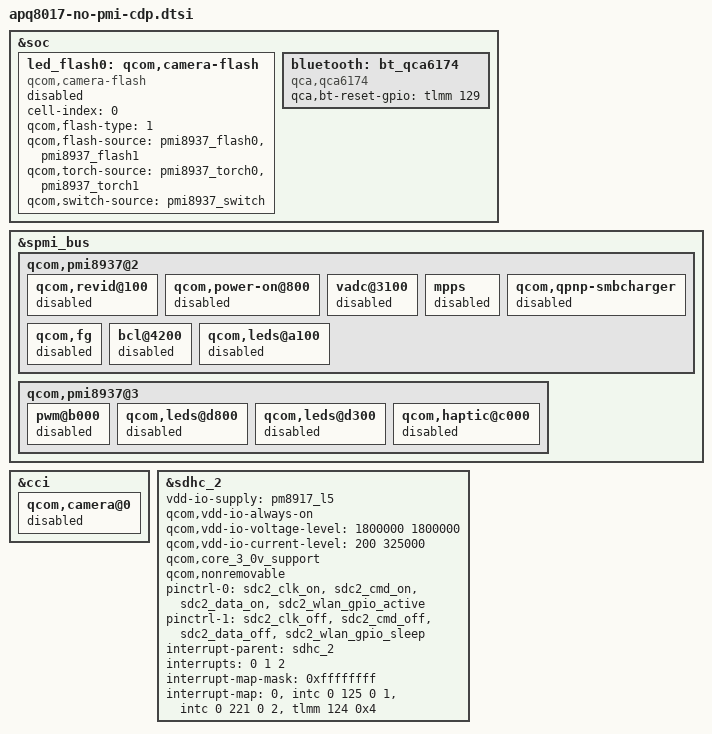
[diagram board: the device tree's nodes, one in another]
/*
 * Copyright (c) 2016, The Linux Foundation. All rights reserved.
 *
 * This program is free software; you can redistribute it and/or modify
 * it under the terms of the GNU General Public License version 2 and
 * only version 2 as published by the Free Software Foundation.
 *
 * This program is distributed in the hope that it will be useful,
 * but WITHOUT ANY WARRANTY; without even the implied warranty of
 * MERCHANTABILITY or FITNESS FOR A PARTICULAR PURPOSE.  See the
 * GNU General Public License for more details.
 */

#include "msm-pmi8937.dtsi"
#include "msm8917-cdp.dtsi"
#include "msm8917-audio-cdp.dtsi"

&soc {
	led_flash0: qcom,camera-flash {
		status = "disabled";
		cell-index = <0>;
		compatible = "qcom,camera-flash";
		qcom,flash-type = <1>;
		qcom,flash-source = <&pmi8937_flash0 &pmi8937_flash1>;
		qcom,torch-source = <&pmi8937_torch0 &pmi8937_torch1>;
		qcom,switch-source = <&pmi8937_switch>;
	};

	bluetooth: bt_qca6174 {
		compatible = "qca,qca6174";
		qca,bt-reset-gpio = <&tlmm 129 0>; /* BT_EN */
	};
};

/* delete all PMI nodes */
&spmi_bus {
	qcom,pmi8937@2 {
		qcom,revid@100 {
			status = "disabled";
		};

		qcom,power-on@800 {
			status = "disabled";
		};

		vadc@3100 {
			status = "disabled";
		};

		mpps {
			status = "disabled";
		};

		qcom,qpnp-smbcharger {
			status = "disabled";
		};

		qcom,fg {
			status = "disabled";
		};

		bcl@4200 {
			status = "disabled";
		};

		qcom,leds@a100 {
			status = "disabled";
		};
	};

	qcom,pmi8937@3 {
		pwm@b000 {
			status = "disabled";
		};

		qcom,leds@d800 {
			status = "disabled";
		};

		qcom,leds@d300 {
			status = "disabled";
		};

		qcom,haptic@c000 {
			status = "disabled";
		};
	};
};

&cci {
	qcom,camera@0 {
		status = "disabled";
	};
};

&sdhc_2 {
	/* device core power supply */
	/delete-property/vdd-supply;
	/delete-property/qcom,vdd-voltage-level;
	/delete-property/qcom,vdd-current-level;

	/* device communication power supply */
	vdd-io-supply = <&pm8917_l5>;
	qcom,vdd-io-always-on;
	qcom,vdd-io-voltage-level = <1800000 1800000>;
	qcom,vdd-io-current-level = <200 325000>;

	qcom,core_3_0v_support;
	qcom,nonremovable;

	pinctrl-names = "active", "sleep";
	pinctrl-0 = <&sdc2_clk_on &sdc2_cmd_on &sdc2_data_on
			&sdc2_wlan_gpio_active>;
	pinctrl-1 = <&sdc2_clk_off &sdc2_cmd_off &sdc2_data_off
			&sdc2_wlan_gpio_sleep>;

	#address-cells = <0>;
	interrupt-parent = <&sdhc_2>;
	interrupts = <0 1 2>;
	#interrupt-cells = <1>;
	interrupt-map-mask = <0xffffffff>;
	interrupt-map = <0 &intc 0 125 0
		1 &intc 0 221 0
		2 &tlmm 124 0x4>;
	interrupt-names = "hc_irq", "pwr_irq", "sdiowakeup_irq";

	/delete-property/cd-gpios;
	/delete-property/qcom,devfreq,freq-table;

	status = "ok";

};
